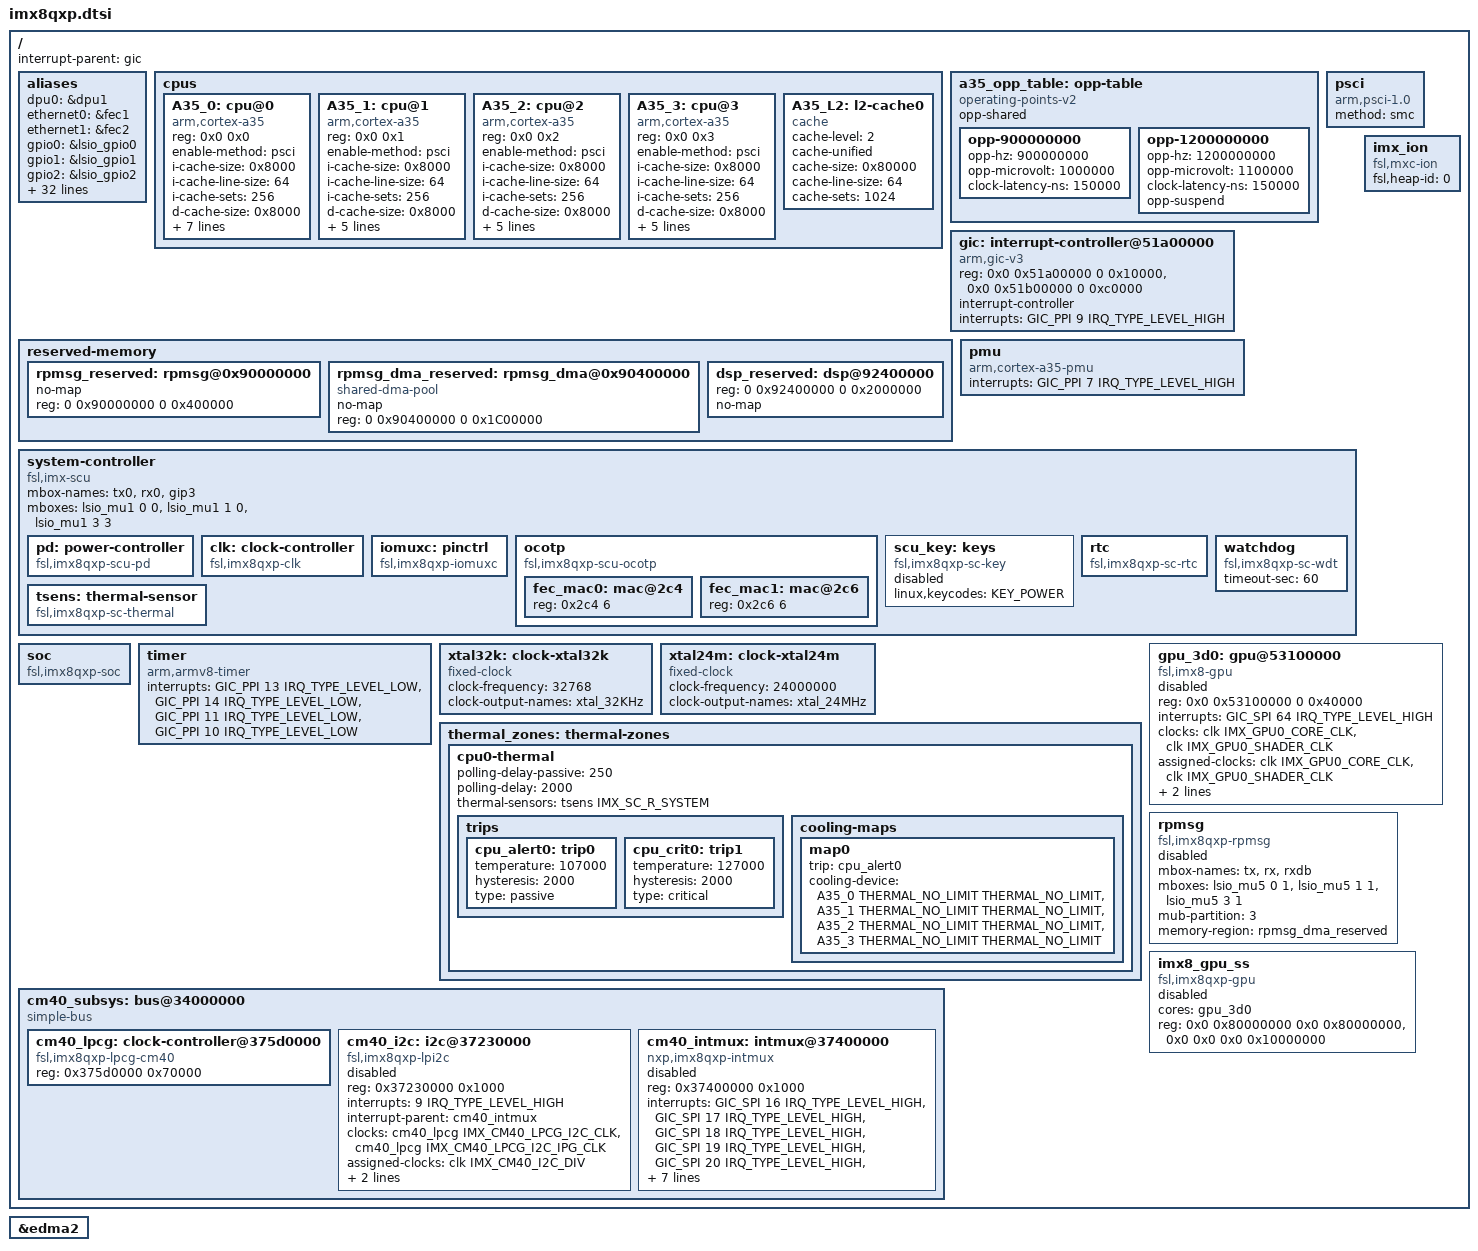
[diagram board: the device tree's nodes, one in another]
// SPDX-License-Identifier: GPL-2.0+
/*
 * Copyright (C) 2016 Freescale Semiconductor, Inc.
 * Copyright 2017-2020 NXP
 *	Dong Aisheng <aisheng.dong@nxp.com>
 */

#include <dt-bindings/clock/imx8-clock.h>
#include <dt-bindings/clock/imx8-lpcg.h>
#include <dt-bindings/firmware/imx/rsrc.h>
#include <dt-bindings/gpio/gpio.h>
#include <dt-bindings/input/input.h>
#include <dt-bindings/interrupt-controller/arm-gic.h>
#include <dt-bindings/pinctrl/pads-imx8qxp.h>
#include <dt-bindings/thermal/thermal.h>

/ {
	interrupt-parent = <&gic>;
	#address-cells = <2>;
	#size-cells = <2>;

	aliases {
		dpu0 = &dpu1;
		ethernet0 = &fec1;
		ethernet1 = &fec2;
		gpio0 = &lsio_gpio0;
		gpio1 = &lsio_gpio1;
		gpio2 = &lsio_gpio2;
		gpio3 = &lsio_gpio3;
		gpio4 = &lsio_gpio4;
		gpio5 = &lsio_gpio5;
		gpio6 = &lsio_gpio6;
		gpio7 = &lsio_gpio7;
		i2c0 = &i2c0;
		i2c1 = &i2c1;
		i2c2 = &i2c2;
		i2c3 = &i2c3;
		ldb0 = &ldb1;
		ldb1 = &ldb2;
		mmc0 = &usdhc1;
		mmc1 = &usdhc2;
		mmc2 = &usdhc3;
		mu0 = &lsio_mu0;
		mu1 = &lsio_mu1;
		mu2 = &lsio_mu2;
		mu3 = &lsio_mu3;
		mu4 = &lsio_mu4;
		serial0 = &lpuart0;
		serial1 = &lpuart1;
		serial2 = &lpuart2;
		serial3 = &lpuart3;
		isi0 = &isi_0;
		isi1 = &isi_1;
		isi2 = &isi_2;
		isi3 = &isi_3;
		isi4 = &isi_4;
		isi5 = &isi_5;
		isi6 = &isi_6;
		isi7 = &isi_7;
		csi0 = &mipi_csi_0;
	};

	cpus {
		#address-cells = <2>;
		#size-cells = <0>;

		/* We have 1 clusters with 4 Cortex-A35 cores */
		A35_0: cpu@0 {
			device_type = "cpu";
			compatible = "arm,cortex-a35";
			reg = <0x0 0x0>;
			enable-method = "psci";
			i-cache-size = <0x8000>;
			i-cache-line-size = <64>;
			i-cache-sets = <256>;
			d-cache-size = <0x8000>;
			d-cache-line-size = <64>;
			d-cache-sets = <128>;
			next-level-cache = <&A35_L2>;
			clocks = <&clk IMX_SC_R_A35 IMX_SC_PM_CLK_CPU>;
			operating-points-v2 = <&a35_opp_table>;
			#cooling-cells = <2>;
		};

		A35_1: cpu@1 {
			device_type = "cpu";
			compatible = "arm,cortex-a35";
			reg = <0x0 0x1>;
			enable-method = "psci";
			i-cache-size = <0x8000>;
			i-cache-line-size = <64>;
			i-cache-sets = <256>;
			d-cache-size = <0x8000>;
			d-cache-line-size = <64>;
			d-cache-sets = <128>;
			next-level-cache = <&A35_L2>;
			clocks = <&clk IMX_SC_R_A35 IMX_SC_PM_CLK_CPU>;
			operating-points-v2 = <&a35_opp_table>;
			#cooling-cells = <2>;
		};

		A35_2: cpu@2 {
			device_type = "cpu";
			compatible = "arm,cortex-a35";
			reg = <0x0 0x2>;
			enable-method = "psci";
			i-cache-size = <0x8000>;
			i-cache-line-size = <64>;
			i-cache-sets = <256>;
			d-cache-size = <0x8000>;
			d-cache-line-size = <64>;
			d-cache-sets = <128>;
			next-level-cache = <&A35_L2>;
			clocks = <&clk IMX_SC_R_A35 IMX_SC_PM_CLK_CPU>;
			operating-points-v2 = <&a35_opp_table>;
			#cooling-cells = <2>;
		};

		A35_3: cpu@3 {
			device_type = "cpu";
			compatible = "arm,cortex-a35";
			reg = <0x0 0x3>;
			enable-method = "psci";
			i-cache-size = <0x8000>;
			i-cache-line-size = <64>;
			i-cache-sets = <256>;
			d-cache-size = <0x8000>;
			d-cache-line-size = <64>;
			d-cache-sets = <128>;
			next-level-cache = <&A35_L2>;
			clocks = <&clk IMX_SC_R_A35 IMX_SC_PM_CLK_CPU>;
			operating-points-v2 = <&a35_opp_table>;
			#cooling-cells = <2>;
		};

		A35_L2: l2-cache0 {
			compatible = "cache";
			cache-level = <2>;
			cache-unified;
			cache-size = <0x80000>;
			cache-line-size = <64>;
			cache-sets = <1024>;
		};
	};

	a35_opp_table: opp-table {
		compatible = "operating-points-v2";
		opp-shared;

		opp-900000000 {
			opp-hz = /bits/ 64 <900000000>;
			opp-microvolt = <1000000>;
			clock-latency-ns = <150000>;
		};

		opp-1200000000 {
			opp-hz = /bits/ 64 <1200000000>;
			opp-microvolt = <1100000>;
			clock-latency-ns = <150000>;
			opp-suspend;
		};
	};

	gic: interrupt-controller@51a00000 {
		compatible = "arm,gic-v3";
		reg = <0x0 0x51a00000 0 0x10000>, /* GIC Dist */
		      <0x0 0x51b00000 0 0xc0000>; /* GICR (RD_base + SGI_base) */
		#interrupt-cells = <3>;
		interrupt-controller;
		interrupts = <GIC_PPI 9 IRQ_TYPE_LEVEL_HIGH>;
	};

	reserved-memory {
		#address-cells = <2>;
		#size-cells = <2>;
		ranges;

		rpmsg_reserved: rpmsg@0x90000000 {
			no-map;
			reg = <0 0x90000000 0 0x400000>;
		};
		rpmsg_dma_reserved:rpmsg_dma@0x90400000 {
			compatible = "shared-dma-pool";
			no-map;
			reg = <0 0x90400000 0 0x1C00000>;
		};
		dsp_reserved: dsp@92400000 {
			reg = <0 0x92400000 0 0x2000000>;
			no-map;
		};
	};

	pmu {
		compatible = "arm,cortex-a35-pmu";
		interrupts = <GIC_PPI 7 IRQ_TYPE_LEVEL_HIGH>;
	};

	psci {
		compatible = "arm,psci-1.0";
		method = "smc";
	};

	system-controller {
		compatible = "fsl,imx-scu";
		mbox-names = "tx0",
			     "rx0",
			     "gip3";
		mboxes = <&lsio_mu1 0 0
			  &lsio_mu1 1 0
			  &lsio_mu1 3 3>;

		pd: power-controller {
			compatible = "fsl,imx8qxp-scu-pd", "fsl,scu-pd";
			#power-domain-cells = <1>;
		};

		clk: clock-controller {
			compatible = "fsl,imx8qxp-clk", "fsl,scu-clk";
			#clock-cells = <2>;
		};

		iomuxc: pinctrl {
			compatible = "fsl,imx8qxp-iomuxc";
		};

		ocotp: ocotp {
			compatible = "fsl,imx8qxp-scu-ocotp";
			#address-cells = <1>;
			#size-cells = <1>;

			fec_mac0: mac@2c4 {
				reg = <0x2c4 6>;
			};

			fec_mac1: mac@2c6 {
				reg = <0x2c6 6>;
			};
		};

		scu_key: keys {
			compatible = "fsl,imx8qxp-sc-key", "fsl,imx-sc-key";
			linux,keycodes = <KEY_POWER>;
			status = "disabled";
		};

		rtc: rtc {
			compatible = "fsl,imx8qxp-sc-rtc";
		};

		watchdog {
			compatible = "fsl,imx8qxp-sc-wdt", "fsl,imx-sc-wdt";
			timeout-sec = <60>;
		};

		tsens: thermal-sensor {
			compatible = "fsl,imx8qxp-sc-thermal", "fsl,imx-sc-thermal";
			#thermal-sensor-cells = <1>;
		};
	};

	soc {
		compatible = "fsl,imx8qxp-soc";
	};

	timer {
		compatible = "arm,armv8-timer";
		interrupts = <GIC_PPI 13 IRQ_TYPE_LEVEL_LOW>, /* Physical Secure */
			     <GIC_PPI 14 IRQ_TYPE_LEVEL_LOW>, /* Physical Non-Secure */
			     <GIC_PPI 11 IRQ_TYPE_LEVEL_LOW>, /* Virtual */
			     <GIC_PPI 10 IRQ_TYPE_LEVEL_LOW>; /* Hypervisor */
	};

	xtal32k: clock-xtal32k {
		compatible = "fixed-clock";
		#clock-cells = <0>;
		clock-frequency = <32768>;
		clock-output-names = "xtal_32KHz";
	};

	xtal24m: clock-xtal24m {
		compatible = "fixed-clock";
		#clock-cells = <0>;
		clock-frequency = <24000000>;
		clock-output-names = "xtal_24MHz";
	};

	thermal_zones: thermal-zones {
		cpu0-thermal {
			polling-delay-passive = <250>;
			polling-delay = <2000>;
			thermal-sensors = <&tsens IMX_SC_R_SYSTEM>;

			trips {
				cpu_alert0: trip0 {
					temperature = <107000>;
					hysteresis = <2000>;
					type = "passive";
				};

				cpu_crit0: trip1 {
					temperature = <127000>;
					hysteresis = <2000>;
					type = "critical";
				};
			};

			cooling-maps {
				map0 {
					trip = <&cpu_alert0>;
					cooling-device =
						<&A35_0 THERMAL_NO_LIMIT THERMAL_NO_LIMIT>,
						<&A35_1 THERMAL_NO_LIMIT THERMAL_NO_LIMIT>,
						<&A35_2 THERMAL_NO_LIMIT THERMAL_NO_LIMIT>,
						<&A35_3 THERMAL_NO_LIMIT THERMAL_NO_LIMIT>;
				};
			};
		};
	};

	imx_ion {
		compatible = "fsl,mxc-ion";
		fsl,heap-id = <0>;
	};

	cm40_subsys: bus@34000000 {
		compatible = "simple-bus";
		#address-cells = <1>;
		#size-cells = <1>;
		ranges = <0x34000000 0x0 0x34000000 0x4000000>;

		cm40_lpcg: clock-controller@375d0000 {
			compatible = "fsl,imx8qxp-lpcg-cm40";
			reg = <0x375d0000 0x70000>;
			#clock-cells = <1>;
		};

		cm40_i2c: i2c@37230000 {
			compatible = "fsl,imx8qxp-lpi2c", "fsl,imx7ulp-lpi2c";
			reg = <0x37230000 0x1000>;
			interrupts = <9 IRQ_TYPE_LEVEL_HIGH>;
			interrupt-parent = <&cm40_intmux>;
			clocks = <&cm40_lpcg IMX_CM40_LPCG_I2C_CLK>,
				 <&cm40_lpcg IMX_CM40_LPCG_I2C_IPG_CLK>;
			clock-names = "per", "ipg";
			assigned-clocks = <&clk IMX_CM40_I2C_DIV>;
			assigned-clock-rates = <24000000>;
			power-domains = <&pd IMX_SC_R_M4_0_I2C>;
			status = "disabled";
		};

		cm40_intmux: intmux@37400000 {
			compatible = "nxp,imx8qxp-intmux", "nxp,imx-intmux";
			reg = <0x37400000 0x1000>;
			interrupts = <GIC_SPI 16 IRQ_TYPE_LEVEL_HIGH>,
				     <GIC_SPI 17 IRQ_TYPE_LEVEL_HIGH>,
				     <GIC_SPI 18 IRQ_TYPE_LEVEL_HIGH>,
				     <GIC_SPI 19 IRQ_TYPE_LEVEL_HIGH>,
				     <GIC_SPI 20 IRQ_TYPE_LEVEL_HIGH>,
				     <GIC_SPI 21 IRQ_TYPE_LEVEL_HIGH>,
				     <GIC_SPI 22 IRQ_TYPE_LEVEL_HIGH>,
				     <GIC_SPI 23 IRQ_TYPE_LEVEL_HIGH>;
			interrupt-controller;
			interrupt-parent = <&gic>;
			#interrupt-cells = <2>;
			clocks = <&clk IMX_CM40_IPG_CLK>;
			clock-names = "ipg";
			power-domains = <&pd IMX_SC_R_M4_0_INTMUX>;
			status = "disabled";
		};
	};

	gpu_3d0: gpu@53100000 {
		compatible = "fsl,imx8-gpu";
		reg = <0x0 0x53100000 0 0x40000>;
		interrupts = <GIC_SPI 64 IRQ_TYPE_LEVEL_HIGH>;
		clocks = <&clk IMX_GPU0_CORE_CLK>, <&clk IMX_GPU0_SHADER_CLK>;
		clock-names = "core", "shader";
		assigned-clocks = <&clk IMX_GPU0_CORE_CLK>, <&clk IMX_GPU0_SHADER_CLK>;
		assigned-clock-rates = <700000000>, <850000000>;
		power-domains = <&pd IMX_SC_R_GPU_0_PID0>;
		status = "disabled";
	};

	rpmsg: rpmsg{
		compatible = "fsl,imx8qxp-rpmsg";
		/* up to now, the following channels are used in imx rpmsg
		 * - tx1/rx1: messages channel.
		 * - general interrupt1: remote proc finish re-init rpmsg stack
		 *   when A core is partition reset.
		 */
		mbox-names = "tx", "rx", "rxdb";
		mboxes = <&lsio_mu5 0 1
			  &lsio_mu5 1 1
			  &lsio_mu5 3 1>;
		mub-partition = <3>;
		memory-region = <&rpmsg_dma_reserved>;
		status = "disabled";
	};

	imx8_gpu_ss: imx8_gpu_ss {
		compatible = "fsl,imx8qxp-gpu", "fsl,imx8-gpu-ss";
		cores = <&gpu_3d0>;
		reg = <0x0 0x80000000 0x0 0x80000000>, <0x0 0x0 0x0 0x10000000>;
		reg-names = "phys_baseaddr", "contiguous_mem";
		status = "disabled";
	};

	/* sorted in register address */
	#include "imx8-ss-img.dtsi"
	#include "imx8-ss-vpu.dtsi"
	#include "imx8-ss-dc.dtsi"
	#include "imx8-ss-lvds.dtsi"
	#include "imx8-ss-adma.dtsi"
	#include "imx8-ss-conn.dtsi"
	#include "imx8-ss-ddr.dtsi"
	#include "imx8-ss-lsio.dtsi"
	#include "imx8-ss-hsio.dtsi"
};

#include "imx8qxp-ss-img.dtsi"
#include "imx8qxp-ss-adma.dtsi"
#include "imx8qxp-ss-conn.dtsi"
#include "imx8qxp-ss-lsio.dtsi"

&edma2 {
	status = "okay";
};

&A35_0 {
	operating-points = <
		/* kHz	uV*/
		/* voltage is maintained by SCFW, so no need here */
		1200000 0
		 900000 0
	>;
	clocks = <&clk IMX_A35_CLK>;
	clock-latency = <61036>;
	#cooling-cells = <2>;
};
